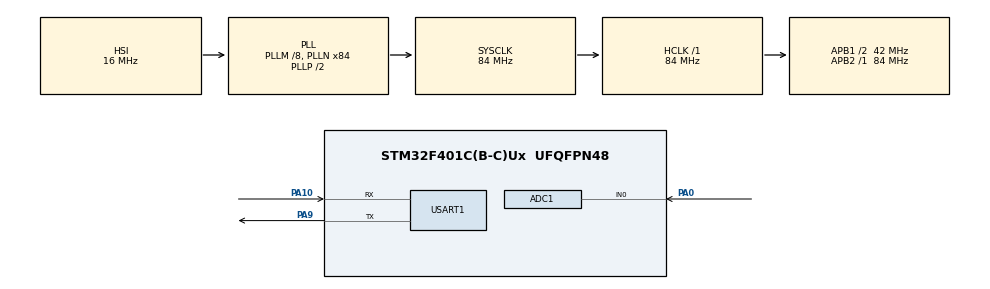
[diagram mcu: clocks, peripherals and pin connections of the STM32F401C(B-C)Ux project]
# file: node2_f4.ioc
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ADC1.Channel-0\#ChannelRegularConversion=ADC_CHANNEL_0
ADC1.NbrOfConversionFlag=1
ADC1.Rank-0\#ChannelRegularConversion=1
ADC1.SamplingTime-0\#ChannelRegularConversion=ADC_SAMPLETIME_3CYCLES
ADC1.master=1
Mcu.Family=STM32F4
Mcu.Name=STM32F401C(B-C)Ux
Mcu.Package=UFQFPN48
NVIC.PriorityGroup=NVIC_PRIORITYGROUP_4
PA0-WKUP.Signal=ADCx_IN0
PA10.Mode=Asynchronous
PA10.Signal=USART1_RX
PA13.Mode=Serial_Wire
PA13.Signal=SYS_JTMS-SWDIO
PA14.Mode=Serial_Wire
PA14.Signal=SYS_JTCK-SWCLK
PA9.Mode=Asynchronous
PA9.Signal=USART1_TX
PH0\ -\ OSC_IN.Mode=HSE-External-Clock-Source
PH0\ -\ OSC_IN.Signal=RCC_OSC_IN
PH1\ -\ OSC_OUT.Mode=HSE-External-Clock-Source
PH1\ -\ OSC_OUT.Signal=RCC_OSC_OUT
ProjectManager.HeapSize=0x200
ProjectManager.StackSize=0x400
ProjectManager.TargetToolchain=STM32CubeIDE
RCC.48MHZClocksFreq_Value=42000000
RCC.AHBFreq_Value=84000000
RCC.APB1CLKDivider=RCC_HCLK_DIV2
RCC.APB1Freq_Value=42000000
RCC.APB1TimFreq_Value=84000000
RCC.APB2Freq_Value=84000000
RCC.APB2TimFreq_Value=84000000
RCC.CortexFreq_Value=84000000
RCC.HCLKFreq_Value=84000000
RCC.HSE_VALUE=25000000
RCC.HSI_VALUE=16000000
RCC.LSE_VALUE=32768
RCC.PLLM=8
RCC.PLLN=84
RCC.SYSCLKFreq_VALUE=84000000
RCC.SYSCLKSource=RCC_SYSCLKSOURCE_PLLCLK
RCC.VCOOutputFreq_Value=168000000
SH.ADCx_IN0.0=ADC1_IN0,IN0
USART1.VirtualMode=VM_ASYNC
board=custom

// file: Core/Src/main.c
/* USER CODE BEGIN Header */
/**
 ******************************************************************************
 * @file           : main.c
 * @brief          : Main program body
 ******************************************************************************
 * @attention
 *
 * Copyright (c) 2026 STMicroelectronics.
 * All rights reserved.
 *
 * This software is licensed under terms that can be found in the LICENSE file
 * in the root directory of this software component.
 * If no LICENSE file comes with this software, it is provided AS-IS.
 *
 ******************************************************************************
 */
/* USER CODE END Header */
#include "main.h"

/* USER CODE BEGIN Includes */
#include "acs712.h"
#include "stdio.h"
#include "math.h"
#include "string.h"
/* USER CODE END Includes */

/* USER CODE BEGIN PD */
#define ADC_MAX 4095.0
#define VREF 3.3

#define SENSITIVITY 0.185
#define SAMPLE_COUNT 1000

#define NOISE_CURRENT 0.15

ACS712_HandleTypeDef acs712;
/* USER CODE END PD */

ADC_HandleTypeDef hadc1;

UART_HandleTypeDef huart1;

/* USER CODE BEGIN PV */
float last_filtered = 0;
float offset = 0;
char msg[100];
char msg1[50];
float energy_Wh = 0;
/* USER CODE END PV */

void SystemClock_Config(void);
static void MX_GPIO_Init(void);
static void MX_ADC1_Init(void);
static void MX_USART1_UART_Init(void);
/* USER CODE BEGIN PFP */
int _write(int file, char *ptr, int len) {
	HAL_UART_Transmit(&huart1, (uint8_t*) ptr, len, HAL_MAX_DELAY);
	return len;
}
/* USER CODE END PFP */

/* USER CODE BEGIN 0 */
void Send_AC(float ac) {
	sprintf(msg, "NODE2:1:AC:%.3f\r\n", ac);
	HAL_UART_Transmit(&huart1, (uint8_t*) msg, strlen(msg), 100);
}

void Send_POWER(float power) {
	sprintf(msg, "NODE2:1:AC_POWER:%.2f\r\n", power);
	HAL_UART_Transmit(&huart1, (uint8_t*) msg, strlen(msg), 100);
}
/* USER CODE END 0 */

int main(void) {

	/* MCU Configuration--------------------------------------------------------*/

	/* Reset of all peripherals, Initializes the Flash interface and the Systick. */
	HAL_Init();

	/* Configure the system clock */
	SystemClock_Config();

	/* Initialize all configured peripherals */
	MX_GPIO_Init();
	MX_ADC1_Init();
	MX_USART1_UART_Init();
	/* USER CODE BEGIN 2 */
	ACS712_Init(&acs712, &hadc1);
	ACS712_Calibrate(&acs712);
	/* USER CODE END 2 */

	/* Infinite loop */
	/* USER CODE BEGIN WHILE */
	while (1) {
		float current = ACS712_ReadCurrent(&acs712);
		float power = ACS712_CalcPower(current);
		float dt = 0.5f / 3600.0f;   // 0.5 giây → giờ
		energy_Wh += power * dt;
		Send_AC(current);
		Send_POWER(power);

		sprintf(msg1, "NODE2:1:ENERGY:%.4f\r\n", energy_Wh);
		HAL_UART_Transmit(&huart1, (uint8_t*) msg, strlen(msg), 100);
		HAL_Delay(500);
		/* USER CODE END WHILE */

	}
}

void SystemClock_Config(void) {
	RCC_OscInitTypeDef RCC_OscInitStruct = { 0 };
	RCC_ClkInitTypeDef RCC_ClkInitStruct = { 0 };

	/** Configure the main internal regulator output voltage
	 */
	__HAL_RCC_PWR_CLK_ENABLE();
	__HAL_PWR_VOLTAGESCALING_CONFIG(PWR_REGULATOR_VOLTAGE_SCALE2);

	/** Initializes the RCC Oscillators according to the specified parameters
	 * in the RCC_OscInitTypeDef structure.
	 */
	RCC_OscInitStruct.OscillatorType = RCC_OSCILLATORTYPE_HSI;
	RCC_OscInitStruct.HSIState = RCC_HSI_ON;
	RCC_OscInitStruct.HSICalibrationValue = RCC_HSICALIBRATION_DEFAULT;
	RCC_OscInitStruct.PLL.PLLState = RCC_PLL_ON;
	RCC_OscInitStruct.PLL.PLLSource = RCC_PLLSOURCE_HSI;
	RCC_OscInitStruct.PLL.PLLM = 8;
	RCC_OscInitStruct.PLL.PLLN = 84;
	RCC_OscInitStruct.PLL.PLLP = RCC_PLLP_DIV2;
	RCC_OscInitStruct.PLL.PLLQ = 4;
	if (HAL_RCC_OscConfig(&RCC_OscInitStruct) != HAL_OK) {
		Error_Handler();
	}

	/** Initializes the CPU, AHB and APB buses clocks
	 */
	RCC_ClkInitStruct.ClockType = RCC_CLOCKTYPE_HCLK | RCC_CLOCKTYPE_SYSCLK
			| RCC_CLOCKTYPE_PCLK1 | RCC_CLOCKTYPE_PCLK2;
	RCC_ClkInitStruct.SYSCLKSource = RCC_SYSCLKSOURCE_PLLCLK;
	RCC_ClkInitStruct.AHBCLKDivider = RCC_SYSCLK_DIV1;
	RCC_ClkInitStruct.APB1CLKDivider = RCC_HCLK_DIV2;
	RCC_ClkInitStruct.APB2CLKDivider = RCC_HCLK_DIV1;

	if (HAL_RCC_ClockConfig(&RCC_ClkInitStruct, FLASH_LATENCY_2) != HAL_OK) {
		Error_Handler();
	}
}

static void MX_ADC1_Init(void) {

	ADC_ChannelConfTypeDef sConfig = { 0 };

	/** Configure the global features of the ADC (Clock, Resolution, Data Alignment and number of conversion)
	 */
	hadc1.Instance = ADC1;
	hadc1.Init.ClockPrescaler = ADC_CLOCK_SYNC_PCLK_DIV4;
	hadc1.Init.Resolution = ADC_RESOLUTION_12B;
	hadc1.Init.ScanConvMode = DISABLE;
	hadc1.Init.ContinuousConvMode = DISABLE;
	hadc1.Init.DiscontinuousConvMode = DISABLE;
	hadc1.Init.ExternalTrigConvEdge = ADC_EXTERNALTRIGCONVEDGE_NONE;
	hadc1.Init.ExternalTrigConv = ADC_SOFTWARE_START;
	hadc1.Init.DataAlign = ADC_DATAALIGN_RIGHT;
	hadc1.Init.NbrOfConversion = 1;
	hadc1.Init.DMAContinuousRequests = DISABLE;
	hadc1.Init.EOCSelection = ADC_EOC_SINGLE_CONV;
	if (HAL_ADC_Init(&hadc1) != HAL_OK) {
		Error_Handler();
	}

	/** Configure for the selected ADC regular channel its corresponding rank in the sequencer and its sample time.
	 */
	sConfig.Channel = ADC_CHANNEL_0;
	sConfig.Rank = 1;
	sConfig.SamplingTime = ADC_SAMPLETIME_144CYCLES;
	if (HAL_ADC_ConfigChannel(&hadc1, &sConfig) != HAL_OK) {
		Error_Handler();
	}

}

static void MX_USART1_UART_Init(void) {

	huart1.Instance = USART1;
	huart1.Init.BaudRate = 115200;
	huart1.Init.WordLength = UART_WORDLENGTH_8B;
	huart1.Init.StopBits = UART_STOPBITS_1;
	huart1.Init.Parity = UART_PARITY_NONE;
	huart1.Init.Mode = UART_MODE_TX_RX;
	huart1.Init.HwFlowCtl = UART_HWCONTROL_NONE;
	huart1.Init.OverSampling = UART_OVERSAMPLING_16;
	if (HAL_UART_Init(&huart1) != HAL_OK) {
		Error_Handler();
	}

}

static void MX_GPIO_Init(void) {

	/* GPIO Ports Clock Enable */
	__HAL_RCC_GPIOH_CLK_ENABLE();
	__HAL_RCC_GPIOA_CLK_ENABLE();

}

void Error_Handler(void) {
	__disable_irq();
	while (1) {
	}
}
